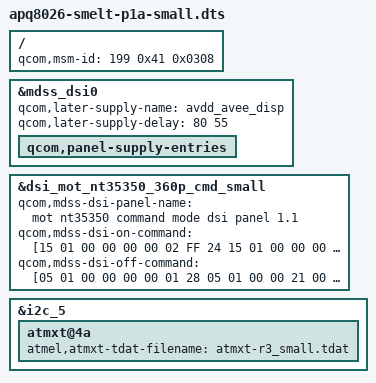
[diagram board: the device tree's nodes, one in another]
/* Copyright (c) 2014, The Linux Foundation. All rights reserved.
 *
 * This program is free software; you can redistribute it and/or modify
 * it under the terms of the GNU General Public License version 2 and
 * only version 2 as published by the Free Software Foundation.
 *
 * This program is distributed in the hope that it will be useful,
 * but WITHOUT ANY WARRANTY; without even the implied warranty of
 * MERCHANTABILITY or FITNESS FOR A PARTICULAR PURPOSE.  See the
 * GNU General Public License for more details.
 */

/dts-v1/;

#include "apq8026-smelt-common.dtsi"
#include "apq8026-smelt-small-tsl2584-config.dtsi"
#include "apq8026-smelt-panel-nt35350-small.dtsi"

/ {
	qcom,msm-id =
		<199 0x41 0x0308>; /* Small P1A Portable (BCM4343W)*/
};

/* workaround to support nt35350 cut 1.1
 * it has current issue that needs turn on avdd/avee later sleep out
 */
&mdss_dsi0 {
	qcom,later-supply-name = "avdd_avee_disp";
	qcom,later-supply-delay = <80 55>;
	qcom,panel-supply-entries {
		/delete-node/ qcom,panel-supply-entry@1;
	};
};
&dsi_mot_nt35350_360p_cmd_small {
	qcom,mdss-dsi-panel-name = "mot nt35350 command mode dsi panel 1.1";
	/* workaround to support nt35350 cut 1.1
	 * it should only change the waiting time of sleep in/out and
	 *   display on/off command to meet panel 1.1 specifications
	 */
	qcom,mdss-dsi-on-command = [15 01 00 00 00 00 02 FF 24
	15 01 00 00 00 00 02 FB 01
	15 01 00 00 00 00 02 93 6D
	15 01 00 00 00 00 02 98 91
	15 01 00 00 00 00 02 FF 10
	15 01 00 00 00 00 02 FB 01
	39 01 00 00 00 00 05 2A 00 00 01 67
	39 01 00 00 00 00 05 2B 00 00 01 67
	15 01 00 00 00 00 02 C0 01
	05 01 00 00 14 00 01 11
	05 01 00 00 28 00 01 29];
	qcom,mdss-dsi-off-command = [05 01 00 00 00 00 01 28
	05 01 00 00 21 00 01 10];
};

&i2c_5 {
	atmxt@4a {
		atmel,atmxt-tdat-filename = "atmxt-r3_small.tdat";
	};
};
